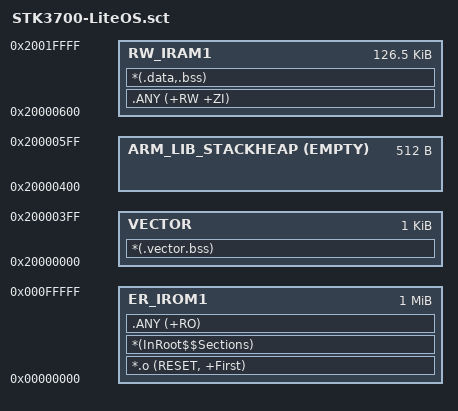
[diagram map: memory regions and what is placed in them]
; *************************************************************
; *** Scatter-Loading Description File generated by uVision ***
; *************************************************************

LR_IROM1 0x00000000 0x00100000  {    ; load region size_region
  ER_IROM1 0x00000000 0x00100000  {  ; load address = execution address
   *.o (RESET, +First)
   *(InRoot$$Sections)
   .ANY (+RO)
  }
  VECTOR 0x20000000  0x400  ; Vector
  {
    *(.vector.bss)
  }
  ARM_LIB_STACKHEAP 0x20000400 EMPTY 0x200
  {
  
  
  }
  RW_IRAM1 0x20000600 0x0001fa00  {  ; RW data
   .ANY (+RW +ZI)
   *(.data,.bss)
  }
}

